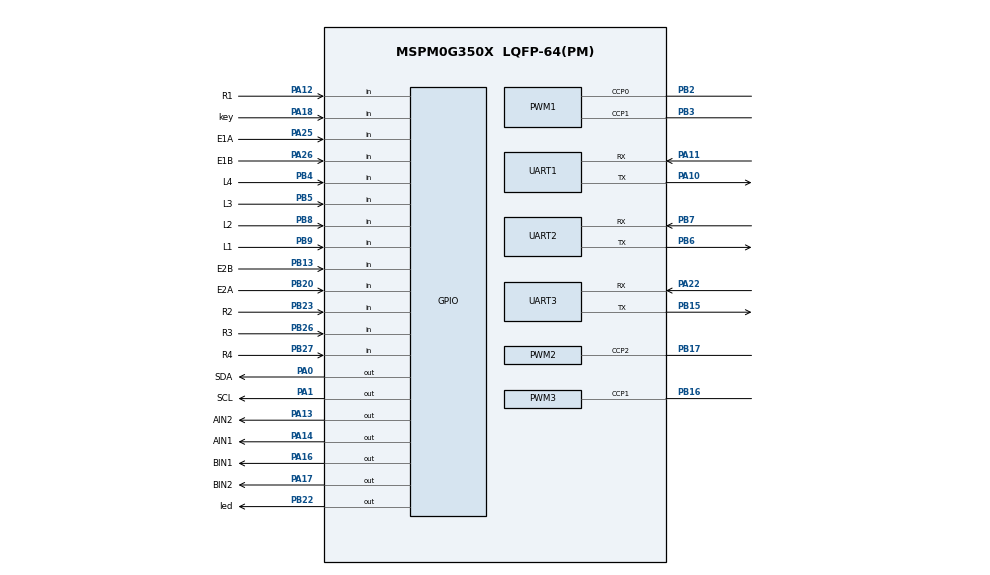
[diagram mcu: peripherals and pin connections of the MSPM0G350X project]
/**
 * @cliArgs --device "MSPM0G350X" --part "Default" --package "LQFP-64(PM)" --product "mspm0_sdk@2.10.00.04"
 * @versions {"tool":"1.26.2+4477"}
 */

/**
 * Import the modules used in this configuration.
 */
const GPIO    = scripting.addModule("/ti/driverlib/GPIO", {}, false);
const GPIO1   = GPIO.addInstance();
const GPIO2   = GPIO.addInstance();
const GPIO3   = GPIO.addInstance();
const GPIO4   = GPIO.addInstance();
const GPIO5   = GPIO.addInstance();
const GPIO6   = GPIO.addInstance();
const GPIO7   = GPIO.addInstance();
const GPIO8   = GPIO.addInstance();
const PWM     = scripting.addModule("/ti/driverlib/PWM", {}, false);
const PWM1    = PWM.addInstance();
const PWM2    = PWM.addInstance();
const PWM3    = PWM.addInstance();
const SYSCTL  = scripting.addModule("/ti/driverlib/SYSCTL");
const SYSTICK = scripting.addModule("/ti/driverlib/SYSTICK");
const TIMER   = scripting.addModule("/ti/driverlib/TIMER", {}, false);
const TIMER1  = TIMER.addInstance();
const TIMER2  = TIMER.addInstance();
const UART    = scripting.addModule("/ti/driverlib/UART", {}, false);
const UART1   = UART.addInstance();
const UART2   = UART.addInstance();
const UART3   = UART.addInstance();

/**
 * Write custom configuration values to the imported modules.
 */
const divider7       = system.clockTree["PLL_PDIV"];
divider7.divideValue = 2;

const divider9       = system.clockTree["UDIV"];
divider9.divideValue = 2;

const gate7  = system.clockTree["MFCLKGATE"];
gate7.enable = true;

const multiplier2         = system.clockTree["PLL_QDIV"];
multiplier2.multiplyValue = 5;

const mux8       = system.clockTree["HSCLKMUX"];
mux8.inputSelect = "HSCLKMUX_SYSPLL2X";

GPIO1.$name                         = "LED";
GPIO1.associatedPins[0].$name       = "led";
GPIO1.associatedPins[0].pin.$assign = "PB22";

const Board = scripting.addModule("/ti/driverlib/Board", {}, false);

GPIO2.$name                          = "BIN";
GPIO2.associatedPins.create(2);
GPIO2.associatedPins[0].$name        = "BIN1";
GPIO2.associatedPins[0].assignedPort = "PORTA";
GPIO2.associatedPins[0].pin.$assign  = "PA16";
GPIO2.associatedPins[1].$name        = "BIN2";
GPIO2.associatedPins[1].assignedPort = "PORTA";
GPIO2.associatedPins[1].pin.$assign  = "PA17";

GPIO3.$name                          = "AIN";
GPIO3.associatedPins.create(2);
GPIO3.associatedPins[0].$name        = "AIN1";
GPIO3.associatedPins[0].assignedPort = "PORTA";
GPIO3.associatedPins[0].pin.$assign  = "PA14";
GPIO3.associatedPins[1].$name        = "AIN2";
GPIO3.associatedPins[1].assignedPort = "PORTA";
GPIO3.associatedPins[1].pin.$assign  = "PA13";

GPIO4.$name                               = "ENCODERA";
GPIO4.associatedPins.create(2);
GPIO4.associatedPins[0].$name             = "E1A";
GPIO4.associatedPins[0].direction         = "INPUT";
GPIO4.associatedPins[0].interruptEn       = true;
GPIO4.associatedPins[0].interruptPriority = "0";
GPIO4.associatedPins[0].polarity          = "RISE";
GPIO4.associatedPins[0].pin.$assign       = "PA25";
GPIO4.associatedPins[1].$name             = "E1B";
GPIO4.associatedPins[1].direction         = "INPUT";
GPIO4.associatedPins[1].interruptEn       = true;
GPIO4.associatedPins[1].interruptPriority = "0";
GPIO4.associatedPins[1].polarity          = "RISE";
GPIO4.associatedPins[1].pin.$assign       = "PA26";

GPIO5.$name                               = "ENCODERB";
GPIO5.associatedPins.create(2);
GPIO5.associatedPins[0].$name             = "E2A";
GPIO5.associatedPins[0].direction         = "INPUT";
GPIO5.associatedPins[0].interruptEn       = true;
GPIO5.associatedPins[0].interruptPriority = "0";
GPIO5.associatedPins[0].polarity          = "RISE";
GPIO5.associatedPins[0].pin.$assign       = "PB20";
GPIO5.associatedPins[1].$name             = "E2B";
GPIO5.associatedPins[1].direction         = "INPUT";
GPIO5.associatedPins[1].interruptEn       = true;
GPIO5.associatedPins[1].interruptPriority = "0";
GPIO5.associatedPins[1].polarity          = "RISE";
GPIO5.associatedPins[1].pin.$assign       = "PB13";

/*
 * 恢复使用原工程的 PA18 外接按键。该按键由外部电路提供稳定电平，
 * 按下时输出高电平，因此不启用 MCU 内部上拉或下拉电阻。
 */
GPIO6.$name                         = "KEY";
GPIO6.associatedPins[0].$name       = "key";
GPIO6.associatedPins[0].direction   = "INPUT";
GPIO6.associatedPins[0].pin.$assign = "PA18";

GPIO7.$name                          = "OLED";
GPIO7.associatedPins.create(2);
GPIO7.associatedPins[0].$name        = "SCL";
GPIO7.associatedPins[0].assignedPort = "PORTA";
GPIO7.associatedPins[0].pin.$assign  = "PA1";
GPIO7.associatedPins[1].$name        = "SDA";
GPIO7.associatedPins[1].assignedPort = "PORTA";
GPIO7.associatedPins[1].pin.$assign  = "PA0";

GPIO8.$name                          = "TRACK";
GPIO8.associatedPins.create(8);
GPIO8.associatedPins[0].$name        = "L4";
GPIO8.associatedPins[0].direction    = "INPUT";
GPIO8.associatedPins[0].internalResistor = "PULL_UP";
GPIO8.associatedPins[0].assignedPort = "PORTB";
GPIO8.associatedPins[0].pin.$assign  = "PB4";
GPIO8.associatedPins[1].$name        = "L3";
GPIO8.associatedPins[1].direction    = "INPUT";
GPIO8.associatedPins[1].internalResistor = "PULL_UP";
GPIO8.associatedPins[1].assignedPort = "PORTB";
GPIO8.associatedPins[1].pin.$assign  = "PB5";
GPIO8.associatedPins[2].$name        = "L2";
GPIO8.associatedPins[2].direction    = "INPUT";
GPIO8.associatedPins[2].internalResistor = "PULL_UP";
GPIO8.associatedPins[2].assignedPort = "PORTB";
GPIO8.associatedPins[2].pin.$assign  = "PB8";
GPIO8.associatedPins[3].$name        = "L1";
GPIO8.associatedPins[3].direction    = "INPUT";
GPIO8.associatedPins[3].internalResistor = "PULL_UP";
GPIO8.associatedPins[3].assignedPort = "PORTB";
GPIO8.associatedPins[3].pin.$assign  = "PB9";
GPIO8.associatedPins[4].$name        = "R1";
GPIO8.associatedPins[4].direction    = "INPUT";
GPIO8.associatedPins[4].internalResistor = "PULL_UP";
GPIO8.associatedPins[4].assignedPort = "PORTA";
GPIO8.associatedPins[4].pin.$assign  = "PA12";
GPIO8.associatedPins[5].$name        = "R2";
GPIO8.associatedPins[5].direction    = "INPUT";
GPIO8.associatedPins[5].internalResistor = "PULL_UP";
GPIO8.associatedPins[5].assignedPort = "PORTB";
GPIO8.associatedPins[5].pin.$assign  = "PB23";
GPIO8.associatedPins[6].$name        = "R3";
GPIO8.associatedPins[6].direction    = "INPUT";
GPIO8.associatedPins[6].internalResistor = "PULL_UP";
GPIO8.associatedPins[6].assignedPort = "PORTB";
GPIO8.associatedPins[6].pin.$assign  = "PB26";
GPIO8.associatedPins[7].$name        = "R4";
GPIO8.associatedPins[7].direction    = "INPUT";
GPIO8.associatedPins[7].internalResistor = "PULL_UP";
GPIO8.associatedPins[7].assignedPort = "PORTB";
GPIO8.associatedPins[7].pin.$assign  = "PB27";

PWM1.$name                      = "PWM_0";
PWM1.timerCount                 = 8000;
PWM1.timerStartTimer            = true;
PWM1.pwmMode                    = "EDGE_ALIGN_UP";
PWM1.peripheral.$assign         = "TIMA1";
PWM1.peripheral.ccp0Pin.$assign = "PB2";
PWM1.peripheral.ccp1Pin.$assign = "PB3";
PWM1.PWM_CHANNEL_0.$name        = "ti_driverlib_pwm_PWMTimerCC0";
PWM1.PWM_CHANNEL_0.ccValue      = 0;
PWM1.PWM_CHANNEL_1.$name        = "ti_driverlib_pwm_PWMTimerCC1";
PWM1.PWM_CHANNEL_1.ccValue      = 0;
PWM1.ccp0PinConfig.$name        = "ti_driverlib_gpio_GPIOPinGeneric2";
PWM1.ccp1PinConfig.$name        = "ti_driverlib_gpio_GPIOPinGeneric3";

PWM2.$name                      = "SERVO_1_PWM";
PWM2.timerCount                 = 20000;
PWM2.clockPrescale              = 80;
PWM2.timerStartTimer            = true;
PWM2.pwmMode                    = "EDGE_ALIGN_UP";
PWM2.ccIndex                    = [2];
PWM2.peripheral.$assign         = "TIMA0";
PWM2.peripheral.ccp2Pin.$assign = "PB17";
PWM2.PWM_CHANNEL_2.$name        = "ti_driverlib_pwm_SERVO1_CC2";
PWM2.PWM_CHANNEL_2.ccValue      = 1500;
PWM2.ccp2PinConfig.$name        = "ti_driverlib_gpio_SERVO1_PWM";

PWM3.$name                      = "SERVO_2_PWM";
PWM3.timerCount                 = 20000;
PWM3.clockPrescale              = 80;
PWM3.timerStartTimer            = true;
PWM3.pwmMode                    = "EDGE_ALIGN_UP";
PWM3.ccIndex                    = [1];
PWM3.peripheral.$assign         = "TIMG7";
PWM3.peripheral.ccp1Pin.$assign = "PB16";
PWM3.PWM_CHANNEL_1.$name        = "ti_driverlib_pwm_SERVO2_CC1";
PWM3.PWM_CHANNEL_1.ccValue      = 1500;
PWM3.ccp1PinConfig.$name        = "ti_driverlib_gpio_SERVO2_PWM";

SYSCTL.forceDefaultClkConfig = true;
SYSCTL.clockTreeEn           = true;

SYSTICK.periodEnable  = true;
SYSTICK.period        = 16777216;
SYSTICK.systickEnable = true;

TIMER1.$name              = "TIMER_0";
TIMER1.timerClkDiv        = 2;
TIMER1.timerClkPrescale   = 32;
TIMER1.timerMode          = "PERIODIC";
TIMER1.timerPeriod        = "10 ms";
TIMER1.timerStartTimer    = true;
TIMER1.interrupts         = ["ZERO"];
TIMER1.peripheral.$assign = "TIMG0";

/*
 * 八路循迹专用 3ms 定时器：
 * 只读取传感器和更新左右目标速度，不占用引脚。
 * 原 TIMER_0 继续保持 10ms，避免改变按键、舵机、JY901 和编码器速度环时序。
 */
TIMER2.$name              = "TRACK_TIMER";
TIMER2.timerClkDiv        = 2;
TIMER2.timerClkPrescale   = 32;
TIMER2.timerMode          = "PERIODIC";
TIMER2.timerPeriod        = "3 ms";
TIMER2.timerStartTimer    = true;
TIMER2.interrupts         = ["ZERO"];
TIMER2.peripheral.$assign = "TIMG6";

UART1.$name                    = "UART_0";
UART1.profile                  = "CONFIG_PROFILE_1";
UART1.peripheral.rxPin.$assign = "PA11";
UART1.peripheral.txPin.$assign = "PA10";
UART1.txPinConfig.$name        = "ti_driverlib_gpio_GPIOPinGeneric0";
UART1.rxPinConfig.$name        = "ti_driverlib_gpio_GPIOPinGeneric1";

/*
 * JY901 姿态传感器专用串口：默认通信格式为 9600、8 数据位、无校验、1 停止位。
 * 使用 UART1 的 PB6/PB7，避开原 UART0(PA10/PA11) 和当前工程中的全部外设引脚。
 */
UART2.$name                            = "JY901_UART";
UART2.profile                          = "CONFIG_PROFILE_1";
UART2.targetBaudRate                   = 9600;
UART2.enableInternalLoopback           = false;
UART2.enableFIFO                       = false;
UART2.enabledInterrupts                = ["RX"];
UART2.peripheral.$assign               = "UART1";
UART2.peripheral.txPin.$assign         = "PB6";
UART2.peripheral.rxPin.$assign         = "PB7";
UART2.txPinConfig.$name                = "JY901_TX";
UART2.rxPinConfig.$name                = "JY901_RX";

/*
 * K230 视觉模块专用串口：
 * PA22 复用为 UART2_RX，PB15 复用为 UART2_TX。
 * 通信格式为 115200 波特率、8 数据位、无校验、1 停止位。
 * RX 使用中断接收，协议解析放在主循环执行，避免影响循迹控制中断。
 */
UART3.$name                            = "K230_UART";
UART3.profile                          = "CONFIG_PROFILE_1";
UART3.targetBaudRate                   = 115200;
UART3.enableInternalLoopback           = false;
UART3.enableFIFO                       = false;
UART3.enabledInterrupts                = ["RX"];
UART3.peripheral.$assign               = "UART2";
UART3.peripheral.rxPin.$assign         = "PA22";
UART3.peripheral.txPin.$assign         = "PB15";
UART3.rxPinConfig.$name                = "K230_RX";
UART3.txPinConfig.$name                = "K230_TX";

/**
 * Pinmux solution for unlocked pins/peripherals. This ensures that minor changes to the automatic solver in a future
 * version of the tool will not impact the pinmux you originally saw.  These lines can be completely deleted in order to
 * re-solve from scratch.
 */
Board.peripheral.$suggestSolution            = "DEBUGSS";
Board.peripheral.swclkPin.$suggestSolution   = "PA20";
Board.peripheral.swdioPin.$suggestSolution   = "PA19";
PWM2.peripheral.$suggestSolution             = "TIMA0";
PWM3.peripheral.$suggestSolution             = "TIMG7";
UART1.peripheral.$suggestSolution            = "UART0";
UART2.peripheral.$suggestSolution            = "UART1";
UART3.peripheral.$suggestSolution            = "UART2";
